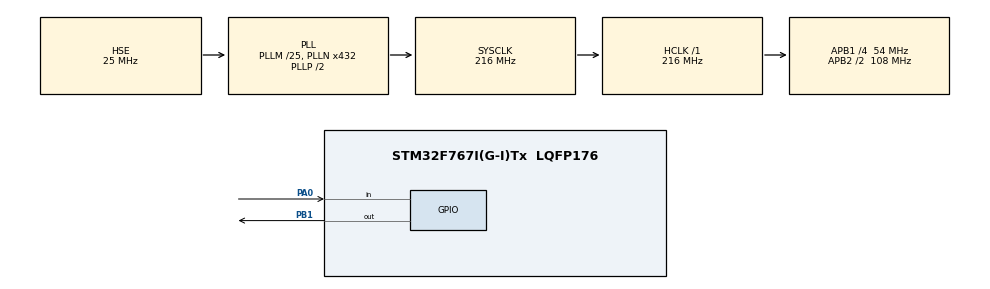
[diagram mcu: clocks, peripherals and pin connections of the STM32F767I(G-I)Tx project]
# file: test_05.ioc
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CORTEX_M7.default_mode_Activation=1
IWDG.Prescaler=IWDG_PRESCALER_64
IWDG.Reload=500
IWDG.Window=0xfff
Mcu.Family=STM32F7
Mcu.Name=STM32F767I(G-I)Tx
Mcu.Package=LQFP176
NVIC.PriorityGroup=NVIC_PRIORITYGROUP_4
PA0/WKUP.GPIO_Mode=GPIO_MODE_INPUT
PA0/WKUP.GPIO_PuPd=GPIO_PULLDOWN
PA0/WKUP.Signal=GPIO_Input
PA13.Mode=Serial_Wire
PA13.Signal=SYS_JTMS-SWDIO
PA14.Mode=Serial_Wire
PA14.Signal=SYS_JTCK-SWCLK
PB1.GPIO_PuPd=GPIO_PULLUP
PB1.GPIO_Speed=GPIO_SPEED_FREQ_HIGH
PB1.PinState=GPIO_PIN_SET
PB1.Signal=GPIO_Output
PH0/OSC_IN.Mode=HSE-External-Oscillator
PH0/OSC_IN.Signal=RCC_OSC_IN
PH1/OSC_OUT.Mode=HSE-External-Oscillator
PH1/OSC_OUT.Signal=RCC_OSC_OUT
ProjectManager.HeapSize=0x200
ProjectManager.StackSize=0x400
ProjectManager.TargetToolchain=MDK-ARM V5.32
RCC.AHBFreq_Value=216000000
RCC.APB1CLKDivider=RCC_HCLK_DIV4
RCC.APB1Freq_Value=54000000
RCC.APB1TimFreq_Value=108000000
RCC.APB2CLKDivider=RCC_HCLK_DIV2
RCC.APB2Freq_Value=108000000
RCC.APB2TimFreq_Value=216000000
RCC.CortexFreq_Value=216000000
RCC.HCLKFreq_Value=216000000
RCC.HSE_VALUE=25000000
RCC.HSI_VALUE=16000000
RCC.LSE_VALUE=32768
RCC.PLLM=25
RCC.PLLN=432
RCC.PLLSourceVirtual=RCC_PLLSOURCE_HSE
RCC.SYSCLKFreq_VALUE=216000000
RCC.SYSCLKSource=RCC_SYSCLKSOURCE_PLLCLK
RCC.USBFreq_Value=216000000
RCC.VCOOutputFreq_Value=432000000
VP_IWDG_VS_IWDG.Mode=IWDG_Activate
board=custom

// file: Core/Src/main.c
/* USER CODE BEGIN Header */
/**
  ******************************************************************************
  * @file           : main.c
  * @brief          : Main program body
  ******************************************************************************
  * @attention
  *
  * Copyright (c) 2022 STMicroelectronics.
  * All rights reserved.
  *
  * This software is licensed under terms that can be found in the LICENSE file
  * in the root directory of this software component.
  * If no LICENSE file comes with this software, it is provided AS-IS.
  *
  ******************************************************************************
  */
/* USER CODE END Header */
#include "main.h"

/* USER CODE BEGIN Includes */
#include "delay.h"
/* USER CODE END Includes */

/* USER CODE BEGIN PD */
#define LED0(n)		(n?HAL_GPIO_WritePin(GPIOB,GPIO_PIN_1,GPIO_PIN_SET):HAL_GPIO_WritePin(GPIOB,GPIO_PIN_1,GPIO_PIN_RESET))
/* USER CODE END PD */

IWDG_HandleTypeDef hiwdg;

/* USER CODE BEGIN PV */
void IWDG_Feed(void);
/* USER CODE END PV */

void SystemClock_Config(void);
static void MPU_Config(void);
static void MX_GPIO_Init(void);
static void MX_IWDG_Init(void);

int main(void)
{

  /* MPU Configuration--------------------------------------------------------*/
  MPU_Config();

  /* MCU Configuration--------------------------------------------------------*/

  /* Reset of all peripherals, Initializes the Flash interface and the Systick. */
  HAL_Init();

  /* Configure the system clock */
  SystemClock_Config();

  /* Initialize all configured peripherals */
  MX_GPIO_Init();
  HAL_Delay(100);
  MX_IWDG_Init();
  /* USER CODE BEGIN 2 */
  LED0(0);		//�ȵ������
  /* USER CODE END 2 */

  /* Infinite loop */
  /* USER CODE BEGIN WHILE */
  while (1)
  {
	 if(HAL_GPIO_ReadPin(GPIOA,GPIO_PIN_0)==GPIO_PIN_SET)
	 {
		 HAL_Delay(10);
		 if(HAL_GPIO_ReadPin(GPIOA,GPIO_PIN_0)==GPIO_PIN_SET)
		 {
			IWDG_Feed();		//ι��
			while(HAL_GPIO_ReadPin(GPIOA,GPIO_PIN_0)==GPIO_PIN_SET);
		 }
	 }

	 HAL_Delay(10);
    /* USER CODE END WHILE */

  }
}

void SystemClock_Config(void)
{
  RCC_OscInitTypeDef RCC_OscInitStruct = {0};
  RCC_ClkInitTypeDef RCC_ClkInitStruct = {0};

  /** Configure the main internal regulator output voltage
  */
  __HAL_RCC_PWR_CLK_ENABLE();
  __HAL_PWR_VOLTAGESCALING_CONFIG(PWR_REGULATOR_VOLTAGE_SCALE1);

  /** Initializes the RCC Oscillators according to the specified parameters
  * in the RCC_OscInitTypeDef structure.
  */
  RCC_OscInitStruct.OscillatorType = RCC_OSCILLATORTYPE_LSI|RCC_OSCILLATORTYPE_HSE;
  RCC_OscInitStruct.HSEState = RCC_HSE_ON;
  RCC_OscInitStruct.LSIState = RCC_LSI_ON;
  RCC_OscInitStruct.PLL.PLLState = RCC_PLL_ON;
  RCC_OscInitStruct.PLL.PLLSource = RCC_PLLSOURCE_HSE;
  RCC_OscInitStruct.PLL.PLLM = 25;
  RCC_OscInitStruct.PLL.PLLN = 432;
  RCC_OscInitStruct.PLL.PLLP = RCC_PLLP_DIV2;
  RCC_OscInitStruct.PLL.PLLQ = 2;
  RCC_OscInitStruct.PLL.PLLR = 2;
  if (HAL_RCC_OscConfig(&RCC_OscInitStruct) != HAL_OK)
  {
    Error_Handler();
  }

  /** Activate the Over-Drive mode
  */
  if (HAL_PWREx_EnableOverDrive() != HAL_OK)
  {
    Error_Handler();
  }

  /** Initializes the CPU, AHB and APB buses clocks
  */
  RCC_ClkInitStruct.ClockType = RCC_CLOCKTYPE_HCLK|RCC_CLOCKTYPE_SYSCLK
                              |RCC_CLOCKTYPE_PCLK1|RCC_CLOCKTYPE_PCLK2;
  RCC_ClkInitStruct.SYSCLKSource = RCC_SYSCLKSOURCE_PLLCLK;
  RCC_ClkInitStruct.AHBCLKDivider = RCC_SYSCLK_DIV1;
  RCC_ClkInitStruct.APB1CLKDivider = RCC_HCLK_DIV4;
  RCC_ClkInitStruct.APB2CLKDivider = RCC_HCLK_DIV2;

  if (HAL_RCC_ClockConfig(&RCC_ClkInitStruct, FLASH_LATENCY_7) != HAL_OK)
  {
    Error_Handler();
  }
}

static void MX_IWDG_Init(void)
{

  hiwdg.Instance = IWDG;
  hiwdg.Init.Prescaler = IWDG_PRESCALER_64;
  hiwdg.Init.Window = 0xfff;
  hiwdg.Init.Reload = 500;
  if (HAL_IWDG_Init(&hiwdg) != HAL_OK)
  {
    Error_Handler();
  }
  /* USER CODE BEGIN IWDG_Init 2 */
  HAL_IWDG_Init(&hiwdg);
  /* USER CODE END IWDG_Init 2 */

}

static void MX_GPIO_Init(void)
{
  GPIO_InitTypeDef GPIO_InitStruct = {0};

  /* GPIO Ports Clock Enable */
  __HAL_RCC_GPIOH_CLK_ENABLE();
  __HAL_RCC_GPIOA_CLK_ENABLE();
  __HAL_RCC_GPIOB_CLK_ENABLE();

  /*Configure GPIO pin Output Level */
  HAL_GPIO_WritePin(GPIOB, GPIO_PIN_1, GPIO_PIN_SET);

  /*Configure GPIO pin : PA0 */
  GPIO_InitStruct.Pin = GPIO_PIN_0;
  GPIO_InitStruct.Mode = GPIO_MODE_INPUT;
  GPIO_InitStruct.Pull = GPIO_PULLDOWN;
  HAL_GPIO_Init(GPIOA, &GPIO_InitStruct);

  /*Configure GPIO pin : PB1 */
  GPIO_InitStruct.Pin = GPIO_PIN_1;
  GPIO_InitStruct.Mode = GPIO_MODE_OUTPUT_PP;
  GPIO_InitStruct.Pull = GPIO_PULLUP;
  GPIO_InitStruct.Speed = GPIO_SPEED_FREQ_HIGH;
  HAL_GPIO_Init(GPIOB, &GPIO_InitStruct);

}

/* USER CODE BEGIN 4 */
//ι�������Ź�
void IWDG_Feed(void)
{
	HAL_IWDG_Refresh(&hiwdg);		//��װ��
}
/* USER CODE END 4 */

/* MPU Configuration */

void MPU_Config(void)
{
  MPU_Region_InitTypeDef MPU_InitStruct = {0};

  /* Disables the MPU */
  HAL_MPU_Disable();

  /** Initializes and configures the Region and the memory to be protected
  */
  MPU_InitStruct.Enable = MPU_REGION_ENABLE;
  MPU_InitStruct.Number = MPU_REGION_NUMBER0;
  MPU_InitStruct.BaseAddress = 0x0;
  MPU_InitStruct.Size = MPU_REGION_SIZE_4GB;
  MPU_InitStruct.SubRegionDisable = 0x87;
  MPU_InitStruct.TypeExtField = MPU_TEX_LEVEL0;
  MPU_InitStruct.AccessPermission = MPU_REGION_NO_ACCESS;
  MPU_InitStruct.DisableExec = MPU_INSTRUCTION_ACCESS_DISABLE;
  MPU_InitStruct.IsShareable = MPU_ACCESS_SHAREABLE;
  MPU_InitStruct.IsCacheable = MPU_ACCESS_NOT_CACHEABLE;
  MPU_InitStruct.IsBufferable = MPU_ACCESS_NOT_BUFFERABLE;

  HAL_MPU_ConfigRegion(&MPU_InitStruct);
  /* Enables the MPU */
  HAL_MPU_Enable(MPU_PRIVILEGED_DEFAULT);

}

void Error_Handler(void)
{
  __disable_irq();
  while (1)
  {
  }
}
